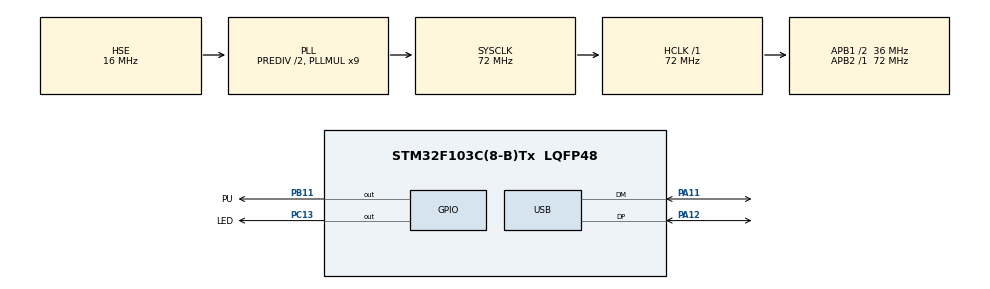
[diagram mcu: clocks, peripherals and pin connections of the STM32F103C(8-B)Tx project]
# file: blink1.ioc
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Mcu.Family=STM32F1
RCC.PLLSourceVirtual=RCC_PLLSOURCE_HSE
USB_DEVICE.CLASS_NAME_FS=MSC
PD1-OSC_OUT.Mode=HSE-External-Oscillator
USB_DEVICE.VirtualModeFS=Msc_FS
PB11.GPIO_Label=PU
PC13-TAMPER-RTC.Signal=GPIO_Output
RCC.USBPrescaler=RCC_USBCLKSOURCE_PLL_DIV1_5
PA11.Mode=Device
PD0-OSC_IN.Signal=RCC_OSC_IN
RCC.APB1CLKDivider=RCC_HCLK_DIV2
PB11.Signal=GPIO_Output
RCC.SYSCLKSource=RCC_SYSCLKSOURCE_PLLCLK
ProjectManager.StackSize=0x400
PD1-OSC_OUT.Signal=RCC_OSC_OUT
PA13.Signal=SYS_JTMS-SWDIO
PA12.Signal=USB_DP
ProjectManager.TargetToolchain=STM32CubeIDE
RCC.HCLKFreq_Value=72000000
RCC.APB2TimFreq_Value=72000000
RCC.USBFreq_Value=48000000
RCC.AHBFreq_Value=72000000
PD0-OSC_IN.Mode=HSE-External-Oscillator
RCC.HSE_VALUE=16000000
board=custom
PC13-TAMPER-RTC.GPIO_Label=LED
RCC.PLLMUL=RCC_PLL_MUL9
RCC.APB2Freq_Value=72000000
USB_DEVICE.USBD_SELF_POWERED=0
PC13-TAMPER-RTC.PinState=GPIO_PIN_SET
PA14.Mode=Serial_Wire
NVIC.USB_LP_CAN1_RX0_IRQn=true\:0\:0\:false\:false\:true\:false\:true
PA13.Mode=Serial_Wire
Mcu.Name=STM32F103C(8-B)Tx
RCC.SYSCLKFreq_VALUE=72000000
Mcu.Package=LQFP48
PC13-TAMPER-RTC.GPIO_ModeDefaultOutputPP=GPIO_MODE_OUTPUT_OD
PA12.Mode=Device
RCC.HSEDivPLL=RCC_HSE_PREDIV_DIV2
PA11.Signal=USB_DM
PA14.Signal=SYS_JTCK-SWCLK
ProjectManager.HeapSize=0x200
PB11.PinState=GPIO_PIN_SET
NVIC.PriorityGroup=NVIC_PRIORITYGROUP_4
RCC.APB1TimFreq_Value=72000000
VP_USB_DEVICE_VS_USB_DEVICE_MSC_FS.Mode=MSC_FS
RCC.APB1Freq_Value=36000000
USB_DEVICE.VirtualMode=Msc

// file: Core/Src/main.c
/* USER CODE BEGIN Header */
/**
  ******************************************************************************
  * @file           : main.c
  * @brief          : Main program body
  ******************************************************************************
  * @attention
  *
  * <h2><center>&copy; Copyright (c) 2021 STMicroelectronics.
  * All rights reserved.</center></h2>
  *
  * This software component is licensed by ST under BSD 3-Clause license,
  * the "License"; You may not use this file except in compliance with the
  * License. You may obtain a copy of the License at:
  *                        opensource.org/licenses/BSD-3-Clause
  *
  ******************************************************************************
  */
/* USER CODE END Header */
#include "main.h"
#include "usb_device.h"

void SystemClock_Config(void);
static void MX_GPIO_Init(void);

int main(void)
{

  /* MCU Configuration--------------------------------------------------------*/

  /* Reset of all peripherals, Initializes the Flash interface and the Systick. */
  HAL_Init();

  /* Configure the system clock */
  SystemClock_Config();

  /* Initialize all configured peripherals */
  MX_GPIO_Init();
  MX_USB_DEVICE_Init();

  /* Infinite loop */
  /* USER CODE BEGIN WHILE */

  uint32_t then = 0, now = 0;

  while (1)
  {

	  now = HAL_GetTick();

	  if (now - then >= 1000) {

		  HAL_GPIO_TogglePin(LED_GPIO_Port, LED_Pin);

		  then = now;
	  }

    /* USER CODE END WHILE */

  }
}

void SystemClock_Config(void)
{
  RCC_OscInitTypeDef RCC_OscInitStruct = {0};
  RCC_ClkInitTypeDef RCC_ClkInitStruct = {0};
  RCC_PeriphCLKInitTypeDef PeriphClkInit = {0};

  /** Initializes the RCC Oscillators according to the specified parameters
  * in the RCC_OscInitTypeDef structure.
  */
  RCC_OscInitStruct.OscillatorType = RCC_OSCILLATORTYPE_HSE;
  RCC_OscInitStruct.HSEState = RCC_HSE_ON;
  RCC_OscInitStruct.HSEPredivValue = RCC_HSE_PREDIV_DIV2;
  RCC_OscInitStruct.HSIState = RCC_HSI_ON;
  RCC_OscInitStruct.PLL.PLLState = RCC_PLL_ON;
  RCC_OscInitStruct.PLL.PLLSource = RCC_PLLSOURCE_HSE;
  RCC_OscInitStruct.PLL.PLLMUL = RCC_PLL_MUL9;
  if (HAL_RCC_OscConfig(&RCC_OscInitStruct) != HAL_OK)
  {
    Error_Handler();
  }
  /** Initializes the CPU, AHB and APB buses clocks
  */
  RCC_ClkInitStruct.ClockType = RCC_CLOCKTYPE_HCLK|RCC_CLOCKTYPE_SYSCLK
                              |RCC_CLOCKTYPE_PCLK1|RCC_CLOCKTYPE_PCLK2;
  RCC_ClkInitStruct.SYSCLKSource = RCC_SYSCLKSOURCE_PLLCLK;
  RCC_ClkInitStruct.AHBCLKDivider = RCC_SYSCLK_DIV1;
  RCC_ClkInitStruct.APB1CLKDivider = RCC_HCLK_DIV2;
  RCC_ClkInitStruct.APB2CLKDivider = RCC_HCLK_DIV1;

  if (HAL_RCC_ClockConfig(&RCC_ClkInitStruct, FLASH_LATENCY_2) != HAL_OK)
  {
    Error_Handler();
  }
  PeriphClkInit.PeriphClockSelection = RCC_PERIPHCLK_USB;
  PeriphClkInit.UsbClockSelection = RCC_USBCLKSOURCE_PLL_DIV1_5;
  if (HAL_RCCEx_PeriphCLKConfig(&PeriphClkInit) != HAL_OK)
  {
    Error_Handler();
  }
}

static void MX_GPIO_Init(void)
{
  GPIO_InitTypeDef GPIO_InitStruct = {0};

  /* GPIO Ports Clock Enable */
  __HAL_RCC_GPIOC_CLK_ENABLE();
  __HAL_RCC_GPIOD_CLK_ENABLE();
  __HAL_RCC_GPIOB_CLK_ENABLE();
  __HAL_RCC_GPIOA_CLK_ENABLE();

  /*Configure GPIO pin Output Level */
  HAL_GPIO_WritePin(LED_GPIO_Port, LED_Pin, GPIO_PIN_SET);

  /*Configure GPIO pin Output Level */
  HAL_GPIO_WritePin(PU_GPIO_Port, PU_Pin, GPIO_PIN_SET);

  /*Configure GPIO pin : LED_Pin */
  GPIO_InitStruct.Pin = LED_Pin;
  GPIO_InitStruct.Mode = GPIO_MODE_OUTPUT_OD;
  GPIO_InitStruct.Pull = GPIO_NOPULL;
  GPIO_InitStruct.Speed = GPIO_SPEED_FREQ_LOW;
  HAL_GPIO_Init(LED_GPIO_Port, &GPIO_InitStruct);

  /*Configure GPIO pin : PU_Pin */
  GPIO_InitStruct.Pin = PU_Pin;
  GPIO_InitStruct.Mode = GPIO_MODE_OUTPUT_PP;
  GPIO_InitStruct.Pull = GPIO_NOPULL;
  GPIO_InitStruct.Speed = GPIO_SPEED_FREQ_LOW;
  HAL_GPIO_Init(PU_GPIO_Port, &GPIO_InitStruct);

}

void Error_Handler(void)
{
  __disable_irq();
  while (1)
  {
  }
}

/************************ (C) COPYRIGHT STMicroelectronics *****END OF FILE****/
